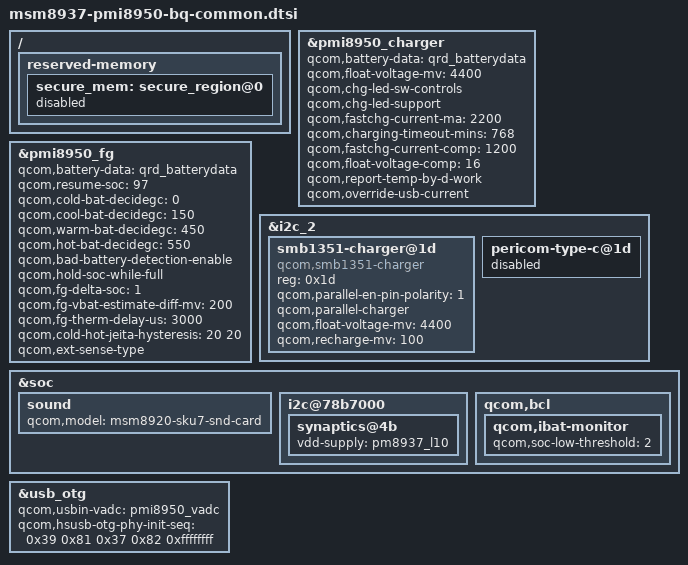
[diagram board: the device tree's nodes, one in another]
/*
 * Copyright (c) 2016, The Linux Foundation. All rights reserved.
 *
 * This program is free software; you can redistribute it and/or modify
 * it under the terms of the GNU General Public License version 2 and
 * only version 2 as published by the Free Software Foundation.
 *
 * This program is distributed in the hope that it will be useful,
 * but WITHOUT ANY WARRANTY; without even the implied warranty of
 * MERCHANTABILITY or FITNESS FOR A PARTICULAR PURPOSE.  See the
 * GNU General Public License for more details.
 */

#include "msm8937.dtsi"
#include "msm8937-pmi8950-qrd-sku1.dtsi"

&pmi8950_charger {
	qcom,battery-data = <&qrd_batterydata>;
	qcom,float-voltage-mv = <4400>;
	qcom,chg-led-sw-controls;
	qcom,chg-led-support;
        //qcom,thermal-mitigation = <2600 2300 1800 1400 900 700 0>;
	qcom,fastchg-current-ma = <2200>;
	qcom,charging-timeout-mins = <768>;
	qcom,fastchg-current-comp = <1200>;
	/* 11 for 4.2V, 16 for 4.1V */
	qcom,float-voltage-comp = <16>;
	qcom,report-temp-by-d-work;
	qcom,override-usb-current;
	status = "okay";
};

&pmi8950_fg {
	qcom,battery-data = <&qrd_batterydata>;
	qcom,resume-soc = <97>;
	qcom,cold-bat-decidegc = <0>;
	qcom,cool-bat-decidegc = <150>;
	qcom,warm-bat-decidegc = <450>;
	qcom,hot-bat-decidegc = <550>;
	qcom,bad-battery-detection-enable;
	qcom,hold-soc-while-full;
	qcom,fg-delta-soc = <1>;
	qcom,fg-vbat-estimate-diff-mv = <200>;
	qcom,fg-therm-delay-us = <3000>;
	qcom,cold-hot-jeita-hysteresis = <20 20>;
	qcom,ext-sense-type;
};

&i2c_2 {
	//Parallel-charger configuration
	smb1351-charger@1d {
		compatible = "qcom,smb1351-charger";
		reg = <0x1d>;
		qcom,parallel-en-pin-polarity = <1>;
		qcom,parallel-charger;
		qcom,float-voltage-mv = <4400>;
		qcom,recharge-mv = <100>;
	};
};

&soc {
	sound {
		qcom,model = "msm8920-sku7-snd-card";
	};

	i2c@78b7000 {
		synaptics@4b {
			vdd-supply = <&pm8937_l10>;
		};
	};
};

&i2c_2 {
	pericom-type-c@1d {
		status="disabled";
	};
};

&usb_otg {
	qcom,usbin-vadc = <&pmi8950_vadc>;
	qcom,hsusb-otg-phy-init-seq = <0x39 0x81 0x37 0x82 0xffffffff>;
};

/ {
	reserved-memory {
		secure_mem: secure_region@0 {
			status="disabled";
		};
	};
};

&soc {
	qcom,bcl {
		qcom,ibat-monitor {
			qcom,soc-low-threshold = <2>;
		};
	};
};
